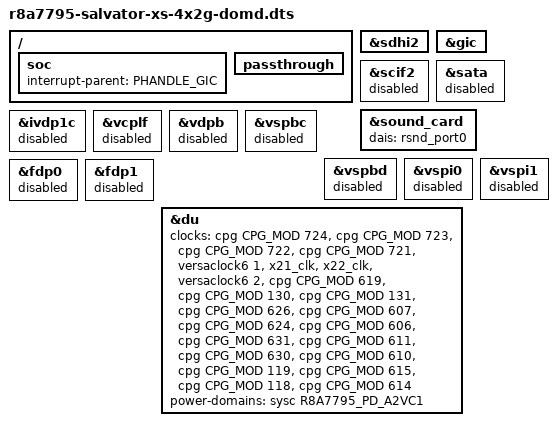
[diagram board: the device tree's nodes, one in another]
/*
 * Device Tree Source for the Salvator-X 2nd version board with R-Car H3 ES3.0
 * running XEN hypervisor
 *
 * Copyright (C) 2018 Renesas Electronics Corp.
 *
 * This file is licensed under the terms of the GNU General Public License
 * version 2.  This program is licensed "as is" without any warranty of any
 * kind, whether express or implied.
 */

#include "r8a7795-salvator-xs.dts"

/*
 * The device tree compiler (DTC) is allocating the phandle from 1 to
 * onwards. Reserve a high value for the GIC phandle.
 */
#define PHANDLE_GIC (65000)

/ {
	soc {
		//this must point to Xen interrupt-parent
		interrupt-parent = <PHANDLE_GIC>;
	};

	passthrough {
	};

	/*
	 * When creating DT for the guest domain Xen inserts only dummy CPU nodes.
	 * And the number of these inserted CPU nodes is equal to the number of
	 * vCPUs assigned to this domain. All CPU properties which original DT has,
	 * such as OPP, clock, regulator, etc are not passed to the guest’s DT.
	 *
	 * Example of guest vCPU node:
	 *
	 * cpu@0 {
	 *     device_type = "cpu";
	 *     compatible = "arm,armv8";
	 *     enable-method = "psci";
	 *     reg = <0x0>;
	 * };
	 *
	 * This results in the fact that all features expecting a57_x or a53_x
	 * CPU nodes to be present get broken. This is why we have to explicitly
	 * remove the following.
	 */
	/delete-node/thermal-zones;
	/delete-node/pmu_a57;
	/delete-node/pmu_a53;
};

/delete-node/&adsp;

&sdhi2 {
	/delete-property/iommus;
};

/* Xen will provide its own GIC, mask ours */
&gic {
	compatible = "";
};

&scif2 {
	status = "disabled";
};

&sata {
	status = "disabled";
};

&sound_card {
	dais = <&rsnd_port0>; /* ak4613 */
};

&ivdp1c {
	status = "disabled";
};

&vcplf {
	status = "disabled";
};

&vdpb {
	status = "disabled";
};

&vspbc {
	status = "disabled";
};

&vspbd {
	status = "disabled";
};

&vspi0 {
	status = "disabled";
};

&vspi1 {
	status = "disabled";
};

&fdp0 {
	status = "disabled";
};

&fdp1 {
	status = "disabled";
};

&du {
	clocks = <&cpg CPG_MOD 724>,
		 <&cpg CPG_MOD 723>,
		 <&cpg CPG_MOD 722>,
		 <&cpg CPG_MOD 721>,
		 <&versaclock6 1>,
		 <&x21_clk>,
		 <&x22_clk>,
		 <&versaclock6 2>,
		 <&cpg CPG_MOD 619>,
		 <&cpg CPG_MOD 130>,
		 <&cpg CPG_MOD 131>,
		 <&cpg CPG_MOD 626>,
		 <&cpg CPG_MOD 607>,
		 <&cpg CPG_MOD 624>,
		 <&cpg CPG_MOD 606>,
		 <&cpg CPG_MOD 631>,
		 <&cpg CPG_MOD 611>,
		 <&cpg CPG_MOD 630>,
		 <&cpg CPG_MOD 610>,
		 <&cpg CPG_MOD 119>,
		 <&cpg CPG_MOD 615>,
		 <&cpg CPG_MOD 118>,
		 <&cpg CPG_MOD 614>;

	clock-names = "du.0", "du.1", "du.2", "du.3",
		      "dclkin.0", "dclkin.1", "dclkin.2", "dclkin.3",
		      "fcpcs", "vcplf", "vdpb",
		      "vspbd_vsp", "vspbd_fcp",
		      "vspbc_vsp", "vspbc_fcp",
		      "vspi0_vsp", "vspi0_fcp",
		      "vspi1_vsp", "vspi1_fcp",
		      "fdp0_vsp", "fdp0_fcp",
		      "fdp1_vsp", "fdp1_fcp";

	power-domains = <&sysc R8A7795_PD_A2VC1>;
};
